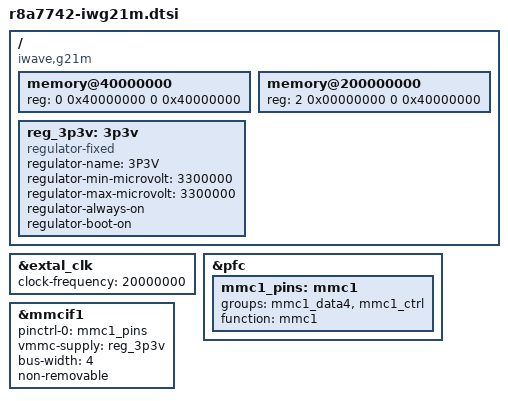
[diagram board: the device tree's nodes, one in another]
// SPDX-License-Identifier: GPL-2.0
/*
 * Device Tree Source for the iWave RZ/G1H Qseven SOM
 *
 * Copyright (C) 2020 Renesas Electronics Corp.
 */

#include "r8a7742.dtsi"
#include <dt-bindings/gpio/gpio.h>

/ {
	compatible = "iwave,g21m", "renesas,r8a7742";

	memory@40000000 {
		device_type = "memory";
		reg = <0 0x40000000 0 0x40000000>;
	};

	memory@200000000 {
		device_type = "memory";
		reg = <2 0x00000000 0 0x40000000>;
	};

	reg_3p3v: 3p3v {
		compatible = "regulator-fixed";
		regulator-name = "3P3V";
		regulator-min-microvolt = <3300000>;
		regulator-max-microvolt = <3300000>;
		regulator-always-on;
		regulator-boot-on;
	};
};

&extal_clk {
	clock-frequency = <20000000>;
};

&pfc {
	mmc1_pins: mmc1 {
		groups = "mmc1_data4", "mmc1_ctrl";
		function = "mmc1";
	};
};

&mmcif1 {
	pinctrl-0 = <&mmc1_pins>;
	pinctrl-names = "default";

	vmmc-supply = <&reg_3p3v>;
	bus-width = <4>;
	non-removable;
	status = "okay";
};
